# M471 register map
File version: 1.0
Registers are 32-bit, read-write, reset 0x0 unless marked. A register's access mark holds for its fields unless they carry their own. Offsets are from the block's base; [hi:lo] are bit positions; {n}, {i} and the like mark numbered series.

## CIR0 — CIR0 Register Map
Base 0x4005F000
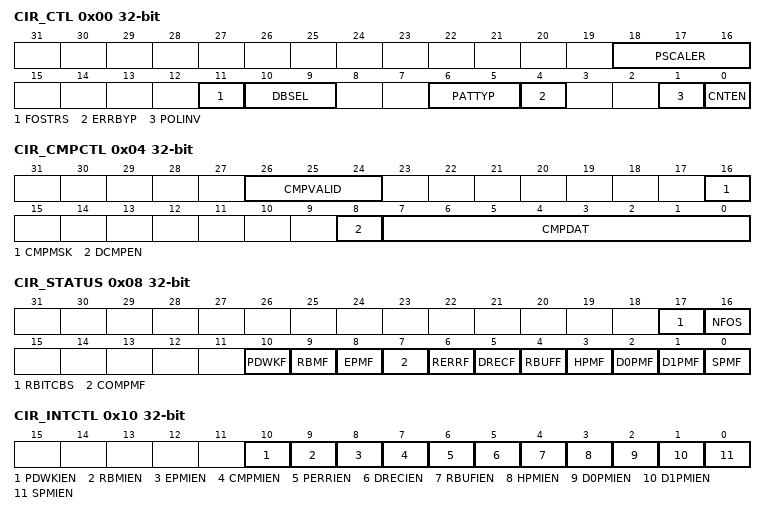
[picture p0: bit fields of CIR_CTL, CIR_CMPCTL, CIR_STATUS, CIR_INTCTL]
0x00 CIR_CTL — CIR Control Register
  [18:16] PSCALER — Sampling Clock Prescaler. Note: The sampling clock should be less than PCLK1.
    0=No prescaler; 1=Prescaler is 2 clocks; 2=Prescaler is 4 clocks; 3=Prescaler is 8 clocks; 4=Prescaler is 16 clocks; 5=Prescaler is 32 clocks; 6=Prescaler is 64 clocks; 7=Prescaler is 128 clocks
  [11] FOSTRS — Filter Output Signal Stored in Register Selection
    0=Filter output signal stored in CIR_STATUS[16] Disabled; 1=Filter output signal stored in CIR_STATUS[16] Enabled
  [10:9] DBSEL — Debounce Sampling Selection
    0=CIR noise filter Disabled; 1=CIR input debounce count Enabled with two sample matched; 2=CIR input debounce count Enabled with three sample matched; 3=CIR input debounce count Enabled with four sample matched
  [6:5] PATTYP — CIR Pattern Format Selection
    0=Standardized positive edge mode; 1=Standardized negative edge mode; 2=Flexible positive edge mode
  [4] ERRBYP — Error Pattern Bypass. Note: 1.If user clears RERRF(CIR_STATUS[6]), then CIR will keep to convert data and store in CIR_DATAx. 2.User must set ERRBYP (CIR_CTL[4]) to 1 before entering Power-down mode.
    0=Data will be dropped if RERRF(CIR_STATUS[6]) is 1; 1=Data will keep to save in DATAx if RERRF(CIR_STATUS[6]) flag is 1
  [1] POLINV — CIR Input Polarity Inverse
    0=CIR input polarity is normal; 1=CIR input polarity is inversed
  [0] CNTEN — CIR Counter Enable. Note: When user changes CNTEN (CIR_CTL[0]) from 0 to 1, system will generate a signal to initialize all interrupt flags, RBITCNT (CIR_RDBC[5:0])and ITVR (CIR_ITVR[31:0]).
    0=CIR counter Disabled; 1=CIR counter Enabled
0x04 CIR_CMPCTL — CIR Data Compare Control Register
  [26:24] CMPVALID — Data Compared Valid Bit Selection. Note: The sampling clock should be less than PCLK1.
    0=Compare bit 0; {v}=Compare bit 0 to bit {v} (v=1..7)
  [16] CMPMSK — Data Compared Mask Initialization. Note: This bit is auto cleared by hardware.
    0=No effect; 1=Re-initialize the data compared match function to monitor DATA0[N:0] (CIR_DATA0[N:0)
  [8] DCMPEN — Data Compared Match Function Selection
    0=Data compared match function Disabled; 1=Data compared match function Enabled
  [7:0] CMPDAT — Compared Match Data. This bit field should be filled with the expected data. It will be compared with CIR_DATA0[N:0]. Note: N is determined by CMPVALID(CIR_CMPCTL[26:24]).
0x08 CIR_STATUS
  [17] RBITCBS — RBITCNT Busy Clearing Status
    0=RBITCNT has completed the clearing process when user writes 1 to RBITCNT(CIR_RDBC[5:0]) or user changes CNTEN (CIR_CTL[0]) from 0 to 1, and system will generate a signal to initialize RBITCNT (CIR_RDBC[5:0]); 1=RBITCNT undergoes clearing process when user writes 1 to RBITCNT(CIR_RDBC[5:0]) or user changes CNTEN (CIR_CTL[0]) from 0 to 1, and system will generate a signal to initialize RBITCNT (CIR_RDBC[5:0])
  [16] NFOS — Noise Filter Output Signal Status
    0=Noise filter output value is 0; 1=Noise filter output value is 1
  [10] PDWKF — Power Down Wake Up Flag. Note: This bit is only cleared by writing 1 to it.
    0=Power down wake up never happened; 1=Power down wake up happened
  [9] RBMF — Receive Bit Match Flag. Note: This bit is only cleared by writing 1 to it.
    0=Receive bit match never happened; 1=Receive bit match happened
  [8] EPMF — End Pattern Match Flag. Note: This bit is only cleared by writing 1 to it.
    0=End pattern match never happened; 1=End pattern match happened
  [7] COMPMF — Compare Match Flag. Note: This bit is only cleared by writing 1 to it.
    0=Compare match never happened; 1=Compare match happened
  [6] RERRF — Receive Error Flag. Note: This bit is only cleared by writing 1 to it.
    0=Receive error never happened; 1=Receive error happened
  [5] DRECF — Data Receive Flag. Note: This bit is only cleared by writing 1 to it.
    0=CIR has not started to convert data; 1=CIR has started to convert data
  [4] RBUFF — Receiving Buffer Full Flag. Note: This bit is only cleared by writing 1 to it.
    0=Receiving buffer full never happened; 1=Receiving buffer full happened
  [3] HPMF — Header Pattern Match Flag. Note: This bit is only cleared by writing 1 to it.
    0=Header pattern never happened; 1=Header pattern happened
  [2] D0PMF — Data0 Pattern Match Flag. Note: This bit is only cleared by writing 1 to it.
    0=Data0 pattern never happened; 1=Data0 pattern happened
  [1] D1PMF — Data1 Pattern Match Flag. Note: This bit is only cleared by writing 1 to it.
    0=Data1 pattern never happened; 1=Data1 pattern happened
  [0] SPMF — Special Pattern Match Flag. Note: This bit is only cleared by writing 1 to it.
    0=Special pattern never happened; 1=Special pattern happened
0x10 CIR_INTCTL — CIR Interrupt Control Register
  [10] PDWKIEN — Power Down Wake-up interrupt Enable Bit
    0=Power down wake-up interrupt Disabled; 1=Power down wake-up interrupt Enabled
  [9] RBMIEN — Receive Bit Match Interrupt Enable Bit
    0=Receive bit match interrupt Disabled; 1=Receive bit match interrupt Enabled
  [8] EPMIEN — End Pattern Match Interrupt Enable Bit
    0=End pattern match interrupt Disabled; 1=End pattern match interrupt Enabled
  [7] CMPMIEN — Compare Match Interrupt Enable Bit
    0=Compare match interrupt Disabled; 1=Compare match interrupt Enabled
  [6] PERRIEN — Pattern Error Interrupt Enable Bit
    0=Pattern error interrupt Disabled; 1=Pattern error interrupt Enabled
  [5] DRECIEN — Data Receive Interrupt Enable Bit
    0=Data receive interrupt Disabled; 1=Data receive interrupt Enabled
  [4] RBUFIEN — Receive Buffer Full Interrupt Enable Bit
    0=Receive buffer full interrupt Disabled; 1=Receive buffer full interrupt Enabled
  [3] HPMIEN — Header Pattern Match Interrupt Enable Bit
    0=Header pattern match interrupt Disabled; 1=Header pattern match interrupt Enabled
  [2] D0PMIEN — Data0 Pattern Match Interrupt Enable Bit
    0=Data0 pattern match interrupt Disabled; 1=Data0 pattern match interrupt Enabled
  [1] D1PMIEN — Data1 Pattern Match Interrupt Enable Bit
    0=Data1 pattern match interrupt Disabled; 1=Data1 pattern match interrupt Enabled
  [0] SPMIEN — Special Pattern Match Interrupt Enable Bit
    0=Special pattern match interrupt Disabled; 1=Special pattern match interrupt Enabled
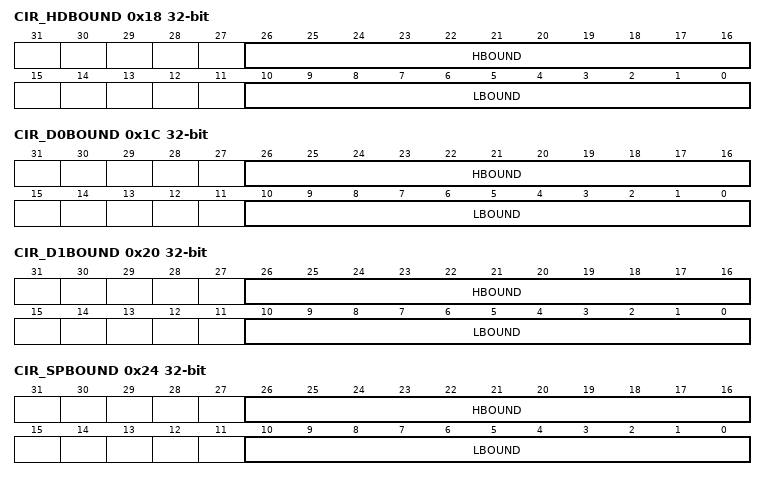
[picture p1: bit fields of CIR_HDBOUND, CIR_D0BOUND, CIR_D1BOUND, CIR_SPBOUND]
0x18 CIR_HDBOUND — CIR Header Pattern Boundry Register
  [26:16] HBOUND — High Boundary Header Pattern. Upper limit of Header pattern input range. Note: If HBOUND and LBOUND are equal to 0, the CIR controller will not monitor the Header pattern boundary.
  [10:0] LBOUND — Low Boundary Header Pattern. Lower limit of Header pattern input range. Note: If HBOUND and LBOUND are equal to 0, the CIR controller will not monitor the Header pattern boundary.
0x1C CIR_D0BOUND — CIR Data 0 Pattern Boundry Register
  [26:16] HBOUND — High Boundary Data0 Pattern. Upper limit of Data 0 pattern input range. Note: If HBOUND and LBOUND are equal to 0, the CIR controller will not monitor the Data0 pattern boundary.
  [10:0] LBOUND — Low Boundary Data0 Pattern. Lower limit of Data 0 pattern input range. Note: If HBOUND and LBOUND are equal to 0, the CIR controller will not monitor the Data0 pattern boundary.
0x20 CIR_D1BOUND — CIR Data 1 Pattern Boundry Register
  [26:16] HBOUND — High Boundary Data 1 Pattern. Upper limit of Data 1 pattern input range. Note: If HBOUND and LBOUND are equal to 0, the CIR controller will not monitor the Data1 pattern boundary.
  [10:0] LBOUND — Low Boundary Data 1 Pattern. Upper limit of Data 1 pattern input range. Note: If HBOUND and LBOUND are equal to 0, the CIR controller will not monitor the Data1 pattern boundary.
0x24 CIR_SPBOUND — CIR Special Pattern Boundry Register
  [26:16] HBOUND — High Boundary Special Pattern. Upper limit of Special pattern input range. Note: If HBOUND and LBOUND are equal to 0, the CIR controller will not monitor the Special pattern boundary.
  [10:0] LBOUND — Low Boundary Special Pattern. Lower limit of Special pattern input range. Note: If HBOUND and LBOUND are equal to 0, the CIR controller will not monitor the Special pattern boundary.
0x28 CIR_ENDBOUND — CIR End Pattern Boundry Register
  [10:0] LBOUND — Low Boundary End Pattern. Lower limit of End pattern input range.
0x38 CIR_LTVR ro — CIR Latch Timer Value Register
  [10:0] LTV — Latch Timer Value. The register is used to record CIR latch timer value. Note: User can only read this register when HPMF (CIR_STATUS[3]), D0PMF (CIR_STATUS[2]), D1PMF (CIR_STATUS[1]), SPMF (CIR_STATUS[0]) or RERRF (CIR_STATUS[6]) occurred.
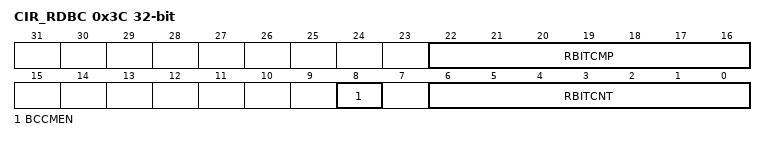
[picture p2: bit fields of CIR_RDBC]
0x3C CIR_RDBC — CIR Receive Data Bit Count Register
  [22:16] RBITCMP — Receive Data Bit Compare Data. User can limit the converted data length by RBITCMP register. When CIR starts to convert data and RBITCNT(CIR_RDBC[5:0]) is equal to RBITCMP (CIR_RDBC[21:16]), the flag RBMF(CIR_STATUS[9]) will be asserted. Note: The maximum value of RBITCMP (CIR_RDBC[22:16]) is 7'h40.
  [8] BCCMEN — Bit Count Compared Match Selection
    0=Bit count compared match function Disabled; 1=Bit count compared match function Enabled
  [6:0] RBITCNT — Receive Data Bit Counts. RBITCNT (CIR_RDBC[5:0]) correspond to CIR_DATA0 and CIR_DATA1 when CIR starts to convert data. Note: 1. User can write 1 to CIR_RDBC[5:0] to clean RBITCNT (CIR_RDBC[5:0]) value. 2. RBITCNT (CIR_RDBC[5:0]) value indicates the amount of data DATA0 (CIR_DATA0) that has already been confirmed. 3. The maximum value of RBITCNT (CIR_RDBC[5:0]) is 7'h40.
0x40 CIR_DATA0 — CIR Receive Data0 Register
  [31:0] DATA0 — CIR DATA0 Register. CIR converts data and stores the data in Data0 when RBITCNT(CIR_RDBC[5:0]) value is between 0 to 31. Note: User can write 1 to CIR_DATA0[31:0] to clean DATA0 value only when the register CNTEN(CIR_CTL[0]) is set to 0.
0x44 CIR_DATA1 — CIR Receive Data1 Register
  [31:0] DATA1 — CIR DATA1 Register. CIR converts data and stores the data in Data1 when RBITCNT(CIR_RDBC[5:0]) value is between 32 to 63. Note: User can write 1 to CIR_DATA1[31:0] to clean DATA1 value only when the register CNTEN(CIR_CTL[0]) is set to 0.
